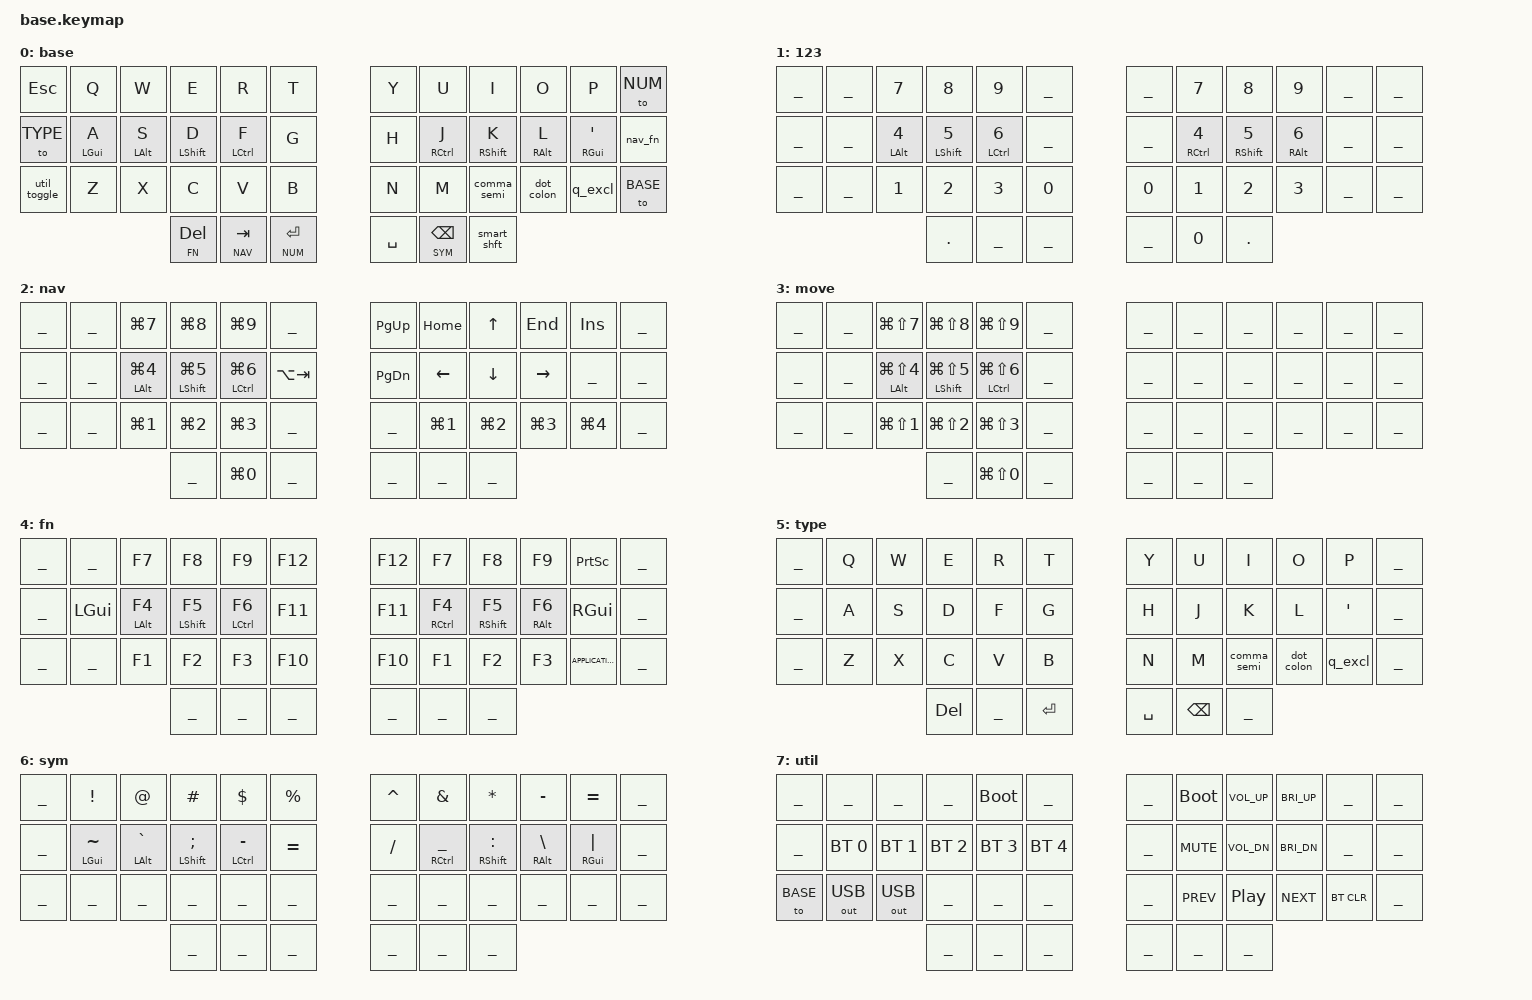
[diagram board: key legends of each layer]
#include <behaviors.dtsi>
#include <dt-bindings/zmk/bt.h>
#include <dt-bindings/zmk/keys.h>
#include <dt-bindings/zmk/outputs.h>

#define BASE    0
#define NUM     1
#define NAV     2
#define MV      3
#define FN      4
#define TYPE    5
#define SYM     6
#define UTIL    7

#include "shared/setup.dtsi"
#include "shared/macros.dtsi"
#include "shared/behaviors.dtsi"
#include "shared/combos.dtsi"

/ {
    keymap {
        compatible = "zmk,keymap";
        base {
            // display-name = "base";   // don't show base layer name
            bindings = <
//          ╭───────────────────┬───────────────────┬───────────────────┬───────────────────┬───────────────────┬───────────────────╮                                           ╭───────────────────┬───────────────────┬───────────────────┬───────────────────┬───────────────────┬───────────────────╮
              &kp ESC             &kp Q               &kp W               &kp E               &kp R               &kp T                                                           &kp Y               &kp U               &kp I               &kp O               &kp P               &to NUM            
//          ├───────────────────┼───────────────────┼───────────────────┼───────────────────┼───────────────────┼───────────────────┤                                           ├───────────────────┼───────────────────┼───────────────────┼───────────────────┼───────────────────┼───────────────────┤
              &to TYPE            &hml LGUI A         &hml LALT S         &hml LSHIFT D       &hml LCTRL F        &kp G                                                           &kp H               &hmr RCTRL J        &hmr RSHIFT K       &hmr RALT L         &hmr RGUI SQT       &nav_fn            
//          ├───────────────────┼───────────────────┼───────────────────┼───────────────────┼───────────────────┼───────────────────┤                                           ├───────────────────┼───────────────────┼───────────────────┼───────────────────┼───────────────────┼───────────────────┤
              &util_toggle         &kp Z               &kp X               &kp C               &kp V               &kp B                                                           &kp N               &kp M               &comma_semi         &dot_colon          &q_excl             &to BASE
                                                                                              &lt FN DEL           &lt NAV TAB         &lt NUM RET             &kp SPACE           &lt SYM BSPC          &smart_shft
//                                                                                          ╰───────────────────┴───────────────────┴───────────────────╯   ╰───────────────────┴───────────────────┴───────────────────╯                                                                                
            >;
        };

        num {
            display-name = "123";
            bindings = <
//          ╭───────────────────┬───────────────────┬───────────────────┬───────────────────┬───────────────────┬───────────────────╮                                           ╭───────────────────┬───────────────────┬───────────────────┬───────────────────┬───────────────────┬───────────────────╮
              ___                 ___                 &kp N7              &kp N8              &kp N9              ___                                                             ___                 &kp N7              &kp N8              &kp N9              ___                 ___                
//          ├───────────────────┼───────────────────┼───────────────────┼───────────────────┼───────────────────┼───────────────────┼                                           ├───────────────────┼───────────────────┼───────────────────┼───────────────────┼───────────────────┼───────────────────┤
              ___                 ___                 &hml LALT N4        &hml LSHIFT N5      &hml LCTRL N6       ___                                                             ___                 &hml RCTRL N4       &hml RSHIFT N5      &hml RALT N6        ___                 ___                
//          ├───────────────────┼───────────────────┼───────────────────┼───────────────────┼───────────────────┼───────────────────┼                                           ├───────────────────┼───────────────────┼───────────────────┼───────────────────┼───────────────────┼───────────────────┤
              ___                 ___                 &kp N1              &kp N2              &kp N3              &kp N0                                                          &kp N0              &kp N1              &kp N2              &kp N3              ___                 ___                
//          ╰───────────────────┴───────────────────┴───────────────────┴───────────────────┴───────────────────┼───────────────────┼───────────────────╮   ╭───────────────────┼───────────────────┼───────────────────┼───────────────────┴───────────────────┴───────────────────┴───────────────────╯
                                                                                              &kp DOT             ___                 ___                     ___                 &kp N0              &kp DOT                                                                                            
//                                                                                          ╰───────────────────┴───────────────────┴───────────────────╯   ╰───────────────────┴───────────────────┴───────────────────╯                                                                                
            >;
        };

        nav {
            display-name = "nav";
            bindings = <
//          ╭───────────────────┬───────────────────┬───────────────────┬───────────────────┬───────────────────┬───────────────────╮                                           ╭───────────────────┬───────────────────┬───────────────────┬───────────────────┬───────────────────┬───────────────────╮
              ___                 ___                 &kp LG(N7)          &kp LG(N8)          &kp LG(N9)          ___                                                             &kp PG_UP           &kp HOME            &kp UP              &kp END             &kp INSERT          ___                
//          ├───────────────────┼───────────────────┼───────────────────┼───────────────────┼───────────────────┼───────────────────┤                                           ├───────────────────┼───────────────────┼───────────────────┼───────────────────┼───────────────────┼───────────────────┤
              ___                 ___                 &hml LALT LG(N4)    &hml LSHIFT LG(N5)  &hml LCTRL LG(N6)   &kp LA(TAB)                                                     &kp PG_DN           &kp LEFT            &kp DOWN            &kp RIGHT           ___                 ___                
//          ├───────────────────┼───────────────────┼───────────────────┼───────────────────┼───────────────────┼───────────────────┤                                           ├───────────────────┼───────────────────┼───────────────────┼───────────────────┼───────────────────┼───────────────────┤
              ___                 ___                 &kp LG(N1)          &kp LG(N2)          &kp LG(N3)          ___                                                             ___                 &kp LG(N1)          &kp LG(N2)          &kp LG(N3)          &kp LG(N4)          ___                
//          ╰───────────────────┴───────────────────┴───────────────────┴───────────────────┴───────────────────┼───────────────────┼───────────────────╮   ╭───────────────────┼───────────────────┼───────────────────┼───────────────────┴───────────────────┴───────────────────┴───────────────────╯
                                                                                              ___                 &kp LG(N0)          ___                     ___                 ___                 ___                                                                                                
//                                                                                          ╰───────────────────┴───────────────────┴───────────────────╯   ╰───────────────────┴───────────────────┴───────────────────╯                                                                                
            >;
        };

        mv {
            display-name = "move";
            bindings = <
//          ╭───────────────────┬───────────────────┬───────────────────┬───────────────────┬───────────────────┬───────────────────╮                                           ╭───────────────────┬───────────────────┬───────────────────┬───────────────────┬───────────────────┬───────────────────╮
              ___                 ___                 &kp LG(LS(N7))      &kp LG(LS(N8))      &kp LG(LS(N9))      ___                                                             ___                 ___                 ___                 ___                 ___                 ___                
//          ├───────────────────┼───────────────────┼───────────────────┼───────────────────┼───────────────────┼───────────────────┤                                           ├───────────────────┼───────────────────┼───────────────────┼───────────────────┼───────────────────┼───────────────────┤
              ___                 ___      &hml LALT LG(LS(N4))    &hml LSHIFT LG(LS(N5))    &hml LCTRL LG(LS(N6))    ___                                                         ___                 ___                 ___                 ___                 ___                 ___                
//          ├───────────────────┼───────────────────┼───────────────────┼───────────────────┼───────────────────┼───────────────────┤                                           ├───────────────────┼───────────────────┼───────────────────┼───────────────────┼───────────────────┼───────────────────┤
              ___                 ___                 &kp LG(LS(N1))      &kp LG(LS(N2))      &kp LG(LS(N3))      ___                                                             ___                 ___                 ___                 ___                 ___                 ___                
//          ╰───────────────────┴───────────────────┴───────────────────┴───────────────────┴───────────────────┼───────────────────┼───────────────────╮   ╭───────────────────┼───────────────────┼───────────────────┼───────────────────┴───────────────────┴───────────────────┴───────────────────╯
                                                                                              ___                 &kp LG(LS(N0))      ___                     ___                 ___                 ___                                                                                                
//                                                                                          ╰───────────────────┴───────────────────┴───────────────────╯   ╰───────────────────┴───────────────────┴───────────────────╯                                                                                
            >;
        };





        fn {
            display-name = "fn";
            bindings = <
//          ╭───────────────────┬───────────────────┬───────────────────┬───────────────────┬───────────────────┬───────────────────╮                                           ╭───────────────────┬───────────────────┬───────────────────┬───────────────────┬───────────────────┬───────────────────╮
              ___                 ___                 &kp F7              &kp F8              &kp F9              &kp F12                                                         &kp F12             &kp F7              &kp F8              &kp F9              &kp PRINTSCREEN     ___                
//          ├───────────────────┼───────────────────┼───────────────────┼───────────────────┼───────────────────┼───────────────────┼                                           ├───────────────────┼───────────────────┼───────────────────┼───────────────────┼───────────────────┼───────────────────┤
              ___                 &kp LGUI            &hml LALT F4        &hml LSHIFT F5      &hml LCTRL F6       &kp F11                                                         &kp F11             &hml RCTRL F4       &hml RSHIFT F5      &hml RALT F6        &kp RGUI            ___                
//          ├───────────────────┼───────────────────┼───────────────────┼───────────────────┼───────────────────┼───────────────────┼                                           ├───────────────────┼───────────────────┼───────────────────┼───────────────────┼───────────────────┼───────────────────┤
              ___                 ___                 &kp F1              &kp F2              &kp F3              &kp F10                                                         &kp F10             &kp F1              &kp F2              &kp F3              &kp K_APPLICATION   ___                
//          ╰───────────────────┴───────────────────┴───────────────────┴───────────────────┴───────────────────┼───────────────────┼───────────────────╮   ╭───────────────────┼───────────────────┼───────────────────┼───────────────────┴───────────────────┴───────────────────┴───────────────────╯
                                                                                              ___                 ___                 ___                     ___                 ___                 ___                                                                                                
//                                                                                          ╰───────────────────┴───────────────────┴───────────────────╯   ╰───────────────────┴───────────────────┴───────────────────╯                                                                                
            >;
        };
        type {
            display-name = "type";
            bindings = <
//          ╭───────────────────┬───────────────────┬───────────────────┬───────────────────┬───────────────────┬───────────────────╮                                           ╭───────────────────┬───────────────────┬───────────────────┬───────────────────┬───────────────────┬───────────────────╮
              ___                 &kp Q               &kp W               &kp E               &kp R               &kp T                                                           &kp Y               &kp U               &kp I               &kp O               &kp P               ___                
//          ├───────────────────┼───────────────────┼───────────────────┼───────────────────┼───────────────────┼───────────────────┤                                           ├───────────────────┼───────────────────┼───────────────────┼───────────────────┼───────────────────┼───────────────────┤
              ___                 &kp A               &kp S               &kp D               &kp F               &kp G                                                           &kp H               &kp J               &kp K               &kp L               &kp SQT             ___                
//          ├───────────────────┼───────────────────┼───────────────────┼───────────────────┼───────────────────┼───────────────────┤                                           ├───────────────────┼───────────────────┼───────────────────┼───────────────────┼───────────────────┼───────────────────┤
              ___                 &kp Z               &kp X               &kp C               &kp V               &kp B                                                           &kp N               &kp M               &comma_semi         &dot_colon          &q_excl             ___                
//          ╰───────────────────┴───────────────────┴───────────────────┴───────────────────┴───────────────────┼───────────────────┼───────────────────╮   ╭───────────────────┼───────────────────┼───────────────────┼───────────────────┴───────────────────┴───────────────────┴───────────────────╯
                                                                                              &kp DEL             ___                 &kp RET                 &kp SPACE           &kp BSPC            ___                                                                                                
//                                                                                          ╰───────────────────┴───────────────────┴───────────────────╯   ╰───────────────────┴───────────────────┴───────────────────╯                                                                                
            >;
        };
        sym {
            display-name = "sym";
            bindings = <
//          ╭───────────────────┬───────────────────┬───────────────────┬───────────────────┬───────────────────┬───────────────────╮                                           ╭───────────────────┬───────────────────┬───────────────────┬───────────────────┬───────────────────┬───────────────────╮
              ___                 &kp EXCL            &kp AT              &kp HASH            &kp DLLR            &kp PRCNT                                                         &kp CARET           &kp AMPS            &kp ASTERISK        &kp MINUS           &kp EQUAL          ___
//          ├───────────────────┼───────────────────┼───────────────────┼───────────────────┼───────────────────┼───────────────────┤                                           ├───────────────────┼───────────────────┼───────────────────┼───────────────────┼───────────────────┼───────────────────┤
              ___                 &hml LGUI TILDE      &hml LALT GRAVE      &hml LSHIFT SEMI      &hml LCTRL MINUS     &kp EQUAL                                                         &kp FSLH            &hmr RCTRL UNDER      &hmr RSHIFT COLON      &hmr RALT BSLH      &hmr RGUI PIPE      ___
//          ├───────────────────┼───────────────────┼───────────────────┼───────────────────┼───────────────────┼───────────────────┼                                           ├───────────────────┼───────────────────┼───────────────────┼───────────────────┼───────────────────┼───────────────────┤
              ___                 ___                 ___                 ___                 ___                 ___                                                             ___                 ___                 ___                 ___                 ___                 ___
//          ╰───────────────────┴───────────────────┴───────────────────┴───────────────────┴───────────────────┴───────────────────┼───────────────────┼───────────────────╮   ╭───────────────────┼───────────────────┼───────────────────┼───────────────────┴───────────────────┴───────────────────┴───────────────────╯
                                                                                              ___                 ___                 ___                     ___                 ___                 ___
//                                                                                          ╰───────────────────┴───────────────────┴───────────────────╯   ╰───────────────────┴───────────────────┴───────────────────╯
            >;
        };
        util {
            display-name = "util";
            bindings = <
//          ╭───────────────────┬───────────────────┬───────────────────┬───────────────────┬───────────────────┬───────────────────╮                                           ╭───────────────────┬───────────────────┬───────────────────┬───────────────────┬───────────────────┬───────────────────╮
              ___                 ___                 ___                 ___                 &bootloader         ___                                                             ___                 &bootloader         &kp C_VOL_UP        &kp C_BRI_UP        ___                 ___
//          ├───────────────────┼───────────────────┼───────────────────┼───────────────────┼───────────────────┼───────────────────┤                                           ├───────────────────┼───────────────────┼───────────────────┼───────────────────┼───────────────────┼───────────────────┤
              ___                 &bt BT_SEL 0        &bt BT_SEL 1        &bt BT_SEL 2        &bt BT_SEL 3        &bt BT_SEL 4                                                    ___                 &kp C_MUTE          &kp C_VOL_DN        &kp C_BRI_DN        ___                 ___
//          ├───────────────────┼───────────────────┼───────────────────┼───────────────────┼───────────────────┼───────────────────┤                                           ├───────────────────┼───────────────────┼───────────────────┼───────────────────┼───────────────────┼───────────────────┤
              &to BASE             &out OUT_USB        &out OUT_USB        ___                 ___                 ___                                                             ___                 &kp C_PREV          &kp C_PLAY_PAUSE    &kp C_NEXT          &bt BT_CLR          ___
//          ╰───────────────────┴───────────────────┴───────────────────┴───────────────────┴───────────────────┼───────────────────┼───────────────────╮   ╭───────────────────┼───────────────────┼───────────────────┼───────────────────┴───────────────────┴───────────────────┴───────────────────╯
                                                                                              ___                 ___                 ___                     ___                 ___                 ___
//                                                                                          ╰───────────────────┴───────────────────┴───────────────────╯   ╰───────────────────┴───────────────────┴───────────────────╯
            >;
        };
    };
};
